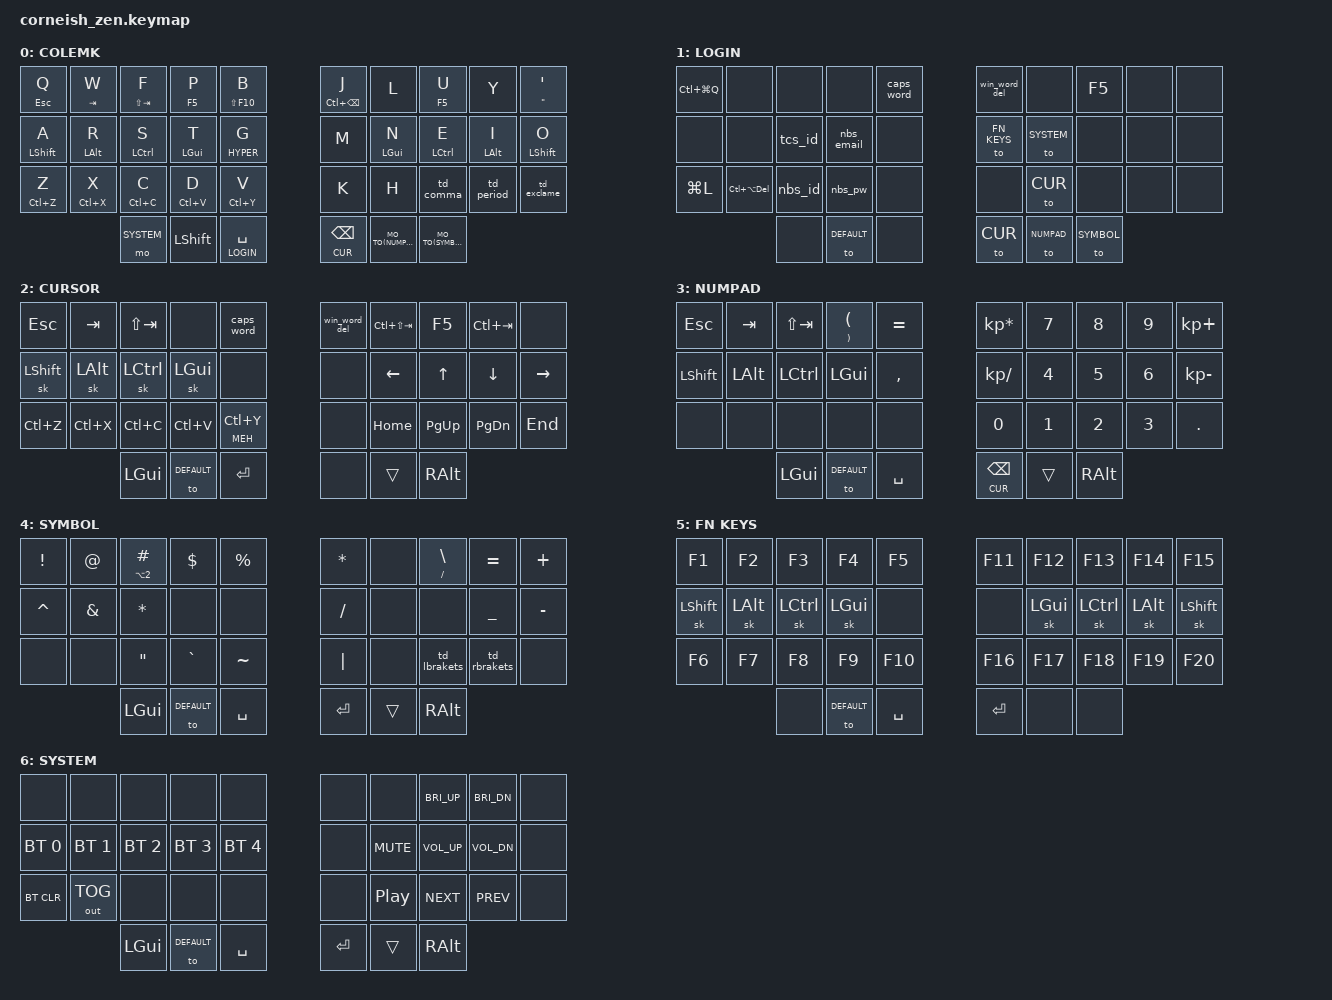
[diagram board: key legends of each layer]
#include <behaviors.dtsi>
#include <dt-bindings/zmk/keys.h>
#include <dt-bindings/zmk/bt.h>
#include <dt-bindings/zmk/outputs.h>

#define DEFAULT 0
#define LOGIN   1
#define CUR     2
#define NUMPAD  3
#define SYMBOL  4
#define FN_KEYS 5
#define SYSTEM  6

// General key definitions
#define MO_TO(layer) &mo_to layer layer   // Macro to apply momentary-layer-on-hold/go-to-layer-on-tap
#define HYPER LA(LS(LC(LGUI))) // definition for a hyper key
#define MEH LA(LS(LCTRL)) // definition for a meta key
// Windows specific definitions
// cut
// copy
// paste
// undo
// redo
// word delete
// tab refresh
// open URL
// Mac OS specific deinitions
#define CUT_M LG(X) // cut
#define COPY_M LG(C) // copy
#define PASTE_M LG(V) // paste
#define UNDO_M LG(Z) // undo
#define REDO_M LS(LG(Z)) // redo
// word delete
#define REFRESH_M LG(R)// tab refresh
#define OPEN_M LG(L)// open URL



/ {
  chosen {
    zmk,matrix_transform = &five_column_transform;
  };
};


#define COMBO(name, keypress, keypos) \
combo_##name {                        \
	timeout-ms = <30>;                \
	bindings = <keypress>;            \
	key-positions = <keypos>;         \
};


&caps_word {
    continue-list = <UNDERSCORE MINUS>;
};


/ {
        behaviors {
        hm: homerow_mods {
                compatible = "zmk,behavior-hold-tap";
                label = "HOMEROW_MODS";
                #binding-cells = <2>;
                tapping_term_ms = <200>;
                flavor = "tap-preferred";
                bindings = <&kp>, <&kp>;
                };

        mo_to: behavior_mo_to {
            compatible = "zmk,behavior-hold-tap";
            label = "mo_to";
            #binding-cells = <2>;
            flavor = "hold-preferred";
            tapping-term-ms = <200>;
            bindings = <&mo>, <&to>;
                };

        td_comma: tap_dance_comma {
            compatible = "zmk,behavior-tap-dance";
            label = "TD_COMMA";
            #binding-cells = <0>;
            tapping-term-ms = <300>;
            bindings = <&kp COMMA>, <&kp SEMI>, <&kp LT>;
                };

        td_exclame: tap_dance_exclame {
            compatible = "zmk,behavior-tap-dance";
            label = "TD_EXCLAME";
            #binding-cells = <0>;
            tapping-term-ms = <300>;
            bindings = <&kp QMARK>, <&kp EXCLAMATION>, <&kp FSLH>;
                };

        td_period: tap_dance_period {
            compatible = "zmk,behavior-tap-dance";
            label = "TD_PERIOD";
            #binding-cells = <0>;
            tapping-term-ms = <300>;
            bindings = <&kp PERIOD>, <&kp COLON>, <&kp GT>;
                };

        td_lbrakets: tap_dance_lbrakets {
            compatible = "zmk,behavior-tap-dance";
            label = "TD_LBRAKETS";
            #binding-cells = <0>;
            tapping-term-ms = <400>;
            bindings = <&kp LPAR>, <&kp LT>, <&kp LBKT>, <&kp LBRC>;
                };

        td_rbrakets: tap_dance_rbrakets {
            compatible = "zmk,behavior-tap-dance";
            label = "TD_RBRAKETS";
            #binding-cells = <0>;
            tapping-term-ms = <400>;
            bindings = <&kp RPAR>, <&kp GT>, <&kp RBKT>, <&kp RBRC>;
                };

                
        };

/* Combo key positions
 0  1  2  3  4          5  6  7  8  9
10 11 12 13 14          15 16 17 18 19
20 21 22 23 24          25 26 27 28 29
      30 31 32          33 34 35            
*/ 

	combos {
		compatible = "zmk,combos";
                // Windows
		COMBO(vol_up, &kp C_VOL_UP, 9 19) // 'o
		COMBO(vol_dn, &kp C_VOL_DN, 19 29) // o?
                // Symbols
                COMBO(l_bracket, &kp LPAR, 4 27) // B<
                COMBO(r_bracket, &kp RPAR, 4 28) // B>
		// Invoke macros
		COMBO(nbs_id, &nbs_id, 18 23) // ID
		COMBO(tcs_id, &tcs_id, 13 22) // TC
                COMBO(nbs_email, &nbs_email, 15 17) // EM
		COMBO(nbs_pw, &nbs_pw, 3 1) // PW
//                COMBO() // LO
//                COMBO() // UL
	};

        
};
 
#define MACRO(name, keys)             \
name: name##_macro {                  \
	label = #name;                    \
	compatible = "zmk,behavior-macro";\
	#binding-cells = <0>;             \
	tap-ms = <1>;                     \
	wait-ms = <1>;                    \
	bindings = <keys>;                \
};



/ {
	macros {
                // NBS
                MACRO(nbs_id, &kp C &kp N5 &kp N0 &kp N1 &kp N3 &kp N0 &kp N5)
                MACRO(nbs_pw, &kp LS(C) &kp O &kp M &kp P &kp E &kp L &kp SEMI &kp LS(P) &kp O &kp L &kp Y)
                MACRO(nbs_email, &kp A &kp R &kp T &kp I &kp S &kp E &kp DOT &kp B &kp R &kp O &kp W &kp N &kp DQT &kp N &kp A &kp T &kp I &kp O &kp N &kp W &kp I &kp D &kp E &kp DOT &kp C &kp O &kp DOT &kp U &kp K)
                // TCS
                MACRO(tcs_id, &kp N2 &kp N4 &kp N4 &kp N0 &kp N8 &kp N8 &kp N2)
                // Windows
                MACRO(win_word_del, &kp LC(BSPC))
                // Mac OS
                MACRO(mac_word_del, &kp LA(BSPC))
	};
};

/ {
        keymap {
                compatible = "zmk,keymap";

                default_layer {
                        label = "COLEMK";
// -----------------------------------------------------------------------------------------
// |   Q   |   W   |   F   |   P   |   B   |              |   J   |   L   |   U   |   Y   |   '   |
// |   A   |   R   |   S   |   T   |   G   |              |   M   |   N   |   E   |   I   |   O   |
// |   Z   |   X   |   C   |   D   |   V   |              |   K   |   H   |   ,   |   .   |   ?   |
//                 |  GUI  |  LWR  |  SPC  |              | BKSPC |  RSE  |  ALT  |
                        bindings = <
&mt ESC Q       &mt TAB W       &mt LS(TAB) F   &mt F5 P        &mt LS(F10) B   &mt LC(BSPC) J  &kp L           &mt F5 U        &kp Y           &mt DQT SQT
&hm LSHFT A     &hm LALT R      &hm LCTRL S     &hm LGUI T      &mt HYPER G     &kp M           &hm LGUI N      &hm LCTRL E     &hm LALT I      &hm LSHFT  O
&mt LC(Z) Z     &mt LC(X) X     &mt LC(C) C     &mt LC(V) D     &mt LC(Y) V     &kp K           &kp H           &td_comma       &td_period      &td_exclame
                                &mo SYSTEM      &kp LSHFT       &lt LOGIN SPACE &lt CUR BSPC    MO_TO(NUMPAD)   MO_TO(SYMBOL)
                        >;
                };

                LOGIN {
                        label = "LOGIN";
// ------------------------------------------------------------------------------------------------------------------------------------------------------------
// |  Mac Lock   |  Mac Login  |   Mac ID    |    Mac PW   |  Caps word  |              |   Word del  |     ---     | Tab Refresh |     ---     |     ---     |
// |     ---     |     ---     |   TCS ID    |   NBS Email |     ---     |              | (TO)Fn keys |  (TO)System |  (TO)Media  |     ---     |     ---     |
// |  Win Lock   |  Win Login  |   NBS ID    |    NBS PW   |     Redo    |              |     ---     |  (TO)Cursor |  (TO)Mouse  |     ---     |     ---     |
//                             |    LGUI     |    DEFAULT  |     RET     |              | (TO)Cursor  |  (TO)Numpad | (TO)Symbols |

                        bindings = <
&kp LC(LG(Q))   &none           &none           &none           &caps_word      &win_word_del   &none           &kp F5          &none           &none
&none           &none           &tcs_id         &nbs_email      &none           &to FN_KEYS     &to SYSTEM      &none           &none           &none
&kp LG(L)       &kp LC(LA(DEL)) &nbs_id         &nbs_pw         &none           &none           &to CUR         &none           &none           &none
                                &none           &to DEFAULT     &none           &to CUR         &to NUMPAD      &to SYMBOL
                        >;
                };

                CUR {
                        label = "CURSOR";
// ------------------------------------------------------------------------------------------------------------------------------------------------------------
// |     ESC     |     F-TAB   |    B-TAB    |     ---     |  Caps word  |              |   Word del  |   Prev Tab  | Tab Refresh |   Next Tab  |     ---     |
// |    LSHFT    |     LALT    |    LCTRL    |     LGUI    |     ---     |              |  Switch app |     Left    |     Up      |     Down    |    Right    |
// |     Undo    |     Cut     |     Copy    |    Paste    |     Redo    |              |    Search   |     Home    |    PG UP    |    PG DN    |     End     |
//                             |     LGUI    |     ---     |     RET     |              |     ---     |     ---     |     RALT    |

                        bindings = <
&kp ESC         &kp TAB         &kp LS(TAB)     &none           &caps_word              &win_word_del   &kp LC(LS(TAB)) &kp F5          &kp LC(TAB)     &none
&sk LSHFT       &sk LALT        &sk LCTRL       &sk LGUI        &none                   &none           &kp LEFT        &kp UP          &kp DOWN        &kp RIGHT
&kp LC(Z)       &kp LC(X)       &kp LC(C)       &kp LC(V)       &mt MEH LC(Y)           &none           &kp HOME        &kp PG_UP       &kp PG_DN       &kp END
                                &kp LGUI        &to DEFAULT     &kp RET                 &none           &trans          &kp RALT
                        >;
                };

                NUMPAD {
                        label = "NUMPAD";
// ------------------------------------------------------------------------------------------------
// |  ESC  | F-TAB | B-TAB |  ( )  |   =   |              |   *   |   7   |   8   |   9   |   +   |
// |  ---  |  ---  |  ---  |  ---  |   ,   |              |   /   |   4   |   5   |   6   |   -   |
// |  ---  |  ---  |  ---  |  ---  |  ---  |              |   0   |   1   |   2   |   3   |   .   |
//                 | LGUI  |  DEF  | SPACE |              |  RTN  |       |  RALT |

                        bindings = <
&kp ESC         &kp TAB         &kp LS(TAB)     &mt RPAR LPAR   &kp EQUAL               &kp KP_MULTIPLY &kp N7          &kp N8          &kp N9          &kp KP_PLUS
&kp LSHFT       &kp LALT        &kp LCTRL       &kp LGUI        &kp COMMA               &kp KP_DIVIDE   &kp N4          &kp N5          &kp N6          &kp KP_MINUS
&none           &none           &none           &none           &none                   &kp N0          &kp N1          &kp N2          &kp N3          &kp PERIOD
                                &kp LGUI        &to DEFAULT     &kp SPACE               &lt CUR BSPC    &trans          &kp RALT
                        >;
                };


                SYMBOL {
                        label = "SYMBOL";
// --------------------------------------------------------------------------------------------------------------------
// |    !    |    @    |    £€   |    $    |    %    |              |    *    |   ---   |   \ /   |    =    |    +    |
// |    ^    |    &    |    *    |  # Win  |  # Mac  |              |    /    |   ---   |   ---   |    _    |    -    |
// |  N-dash |  M-dash |    "    |    `    |    ~    |              |    |    |   ---   | ( < [ { | ) > ] } |   ---   |
//                     |   GUI   |         |   SPC   |              |   ENT   |         |   ALT   |

                        bindings = <
&kp EXCL        &kp AT          &mt LA(N2) POUND        &kp DLLR        &kp PRCNT               &kp ASTRK       &none           &mt FSLH BSLH   &kp EQUAL       &kp PLUS
&kp CARET       &kp AMPS        &kp ASTRK               &none           &none                   &kp FSLH        &none           &none           &kp UNDER       &kp MINUS
&none           &none           &kp DQT                 &kp GRAVE       &kp TILDE               &kp PIPE        &none           &td_lbrakets    &td_rbrakets    &none
                                &kp LGUI                &to DEFAULT     &kp SPACE               &kp RET         &trans          &kp RALT
                        >;
                };

                FN_KEYS {
                        label = "FN KEYS";
// -----------------------------------------------------------------------------------------
// |  F1   |  F2   |  F3   |  F4   |  F5   |              |  F11  |  F12  |  F12  |  F14  |  F15  |
// |  LS   |  LA   |  LC   |  LG   |  ---  |              |  ---  |  LG   |  LC   |  LA   |  LS   |
// |  F6   |  F7   |  F8   |  F9   |  F10  |              |  F16  |  F17  |  F18  |  F19  |  F20  |
//                 |  ---  |  ---  |  SPC  |              |  ENT  |  ---  |  ---  |

                        bindings = <
&kp F1          &kp F2          &kp F3       &kp F4             &kp F5          &kp F11         &kp F12         &kp F13         &kp F14         &kp F15
&sk LSHFT       &sk LALT        &sk LCTRL    &sk LGUI           &none           &none           &sk LGUI        &sk LCTRL       &sk LALT        &sk LSHFT
&kp F6          &kp F7          &kp F8       &kp F9             &kp F10         &kp F16         &kp F17         &kp F18         &kp F19         &kp F20
                                &none        &to DEFAULT        &kp SPACE       &kp RET         &none           &none
                        >;
                };

                SYSTEM {
                        label = "SYSTEM";
// ------------------------------------------------------------------------------------------------------------------------------------------------------------
// |    Power    |             |             |             |             |              | Screen Shot |             |  Bright Up  | Bright Down |             |
// |     BT1     |     BT2     |     BT3     |     BT4     |     BT5     |              |             |    V.Mute   |     V.Up    |    V.Down   |             |
// |    BTCLR    |   BT/USB    |             |             |             |              |             | Play/Pause  |     Next    |   Previous  |             |
//                             |     GUI     |             |     SPC     |              |     ENT     |             |     ALT     |

                        bindings = <
&none           &none           &none           &none           &none                   &none           &none           &kp C_BRI_UP    &kp C_BRI_DN    &none
&bt BT_SEL 0    &bt BT_SEL 1    &bt BT_SEL 2    &bt BT_SEL 3    &bt BT_SEL 4            &none           &kp C_MUTE      &kp C_VOL_UP    &kp C_VOL_DN    &none
&bt BT_CLR      &out OUT_TOG    &none           &none           &none                   &none           &kp C_PP        &kp C_NEXT      &kp C_PREV      &none
                                &kp LGUI        &to DEFAULT     &kp SPACE               &kp RET         &trans          &kp RALT
                        >;
                };


        };
};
